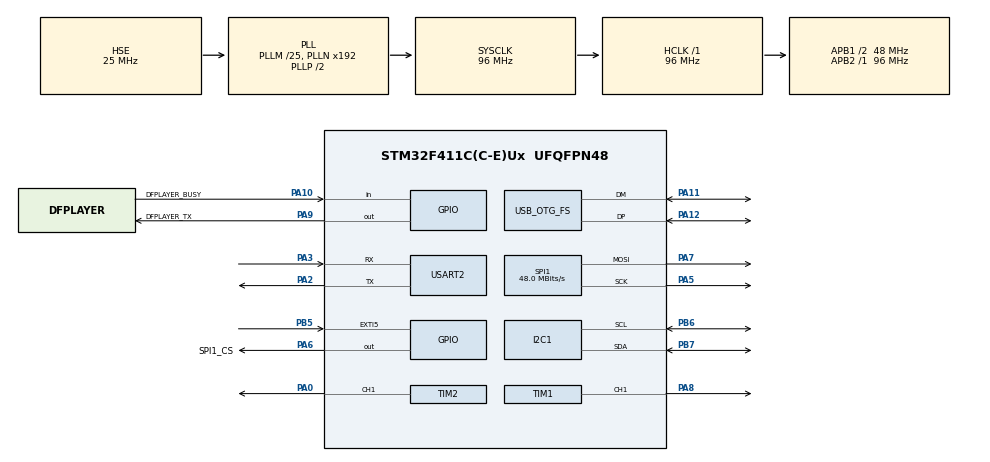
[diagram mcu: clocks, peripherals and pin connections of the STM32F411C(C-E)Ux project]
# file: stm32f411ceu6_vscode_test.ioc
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Dma.Request0=USART2_RX
Dma.Request1=USART2_TX
Dma.Request2=TIM2_CH1
Dma.TIM2_CH1.2.Direction=DMA_MEMORY_TO_PERIPH
Dma.TIM2_CH1.2.FIFOMode=DMA_FIFOMODE_DISABLE
Dma.TIM2_CH1.2.Instance=DMA1_Stream5
Dma.TIM2_CH1.2.MemDataAlignment=DMA_MDATAALIGN_WORD
Dma.TIM2_CH1.2.MemInc=DMA_MINC_ENABLE
Dma.TIM2_CH1.2.Mode=DMA_NORMAL
Dma.TIM2_CH1.2.PeriphDataAlignment=DMA_PDATAALIGN_WORD
Dma.TIM2_CH1.2.PeriphInc=DMA_PINC_DISABLE
Dma.TIM2_CH1.2.Priority=DMA_PRIORITY_HIGH
Dma.USART2_RX.0.Direction=DMA_PERIPH_TO_MEMORY
Dma.USART2_RX.0.FIFOMode=DMA_FIFOMODE_DISABLE
Dma.USART2_RX.0.Instance=DMA1_Stream7
Dma.USART2_RX.0.MemDataAlignment=DMA_MDATAALIGN_BYTE
Dma.USART2_RX.0.MemInc=DMA_MINC_ENABLE
Dma.USART2_RX.0.Mode=DMA_CIRCULAR
Dma.USART2_RX.0.PeriphDataAlignment=DMA_PDATAALIGN_BYTE
Dma.USART2_RX.0.PeriphInc=DMA_PINC_DISABLE
Dma.USART2_RX.0.Priority=DMA_PRIORITY_MEDIUM
Dma.USART2_TX.1.Direction=DMA_MEMORY_TO_PERIPH
Dma.USART2_TX.1.FIFOMode=DMA_FIFOMODE_DISABLE
Dma.USART2_TX.1.Instance=DMA1_Stream6
Dma.USART2_TX.1.MemDataAlignment=DMA_MDATAALIGN_BYTE
Dma.USART2_TX.1.MemInc=DMA_MINC_ENABLE
Dma.USART2_TX.1.Mode=DMA_NORMAL
Dma.USART2_TX.1.PeriphDataAlignment=DMA_PDATAALIGN_BYTE
Dma.USART2_TX.1.PeriphInc=DMA_PINC_DISABLE
Dma.USART2_TX.1.Priority=DMA_PRIORITY_MEDIUM
Mcu.Family=STM32F4
Mcu.Name=STM32F411C(C-E)Ux
Mcu.Package=UFQFPN48
NVIC.DMA1_Stream5_IRQn=true\:0\:0\:true\:false\:true\:false\:true\:true
NVIC.DMA1_Stream6_IRQn=true\:5\:0\:true\:false\:true\:false\:true\:true
NVIC.DMA1_Stream7_IRQn=true\:5\:0\:false\:false\:true\:false\:true\:true
NVIC.EXTI9_5_IRQn=true\:0\:0\:false\:false\:true\:true\:true\:true
NVIC.OTG_FS_IRQn=true\:0\:0\:false\:false\:true\:false\:true\:true
NVIC.PriorityGroup=NVIC_PRIORITYGROUP_4
NVIC.TIM2_IRQn=true\:0\:0\:false\:false\:true\:true\:true\:true
NVIC.TIM3_IRQn=true\:0\:0\:false\:false\:true\:true\:true\:true
NVIC.USART2_IRQn=true\:5\:0\:true\:false\:true\:true\:true\:true
PA0-WKUP.GPIO_Speed=GPIO_SPEED_FREQ_VERY_HIGH
PA0-WKUP.Signal=S_TIM2_CH1_ETR
PA10.GPIO_Label=DFPLAYER_BUSY
PA10.GPIO_PuPd=GPIO_PULLUP
PA10.Signal=GPIO_Input
PA11.Mode=Device_Only
PA11.Signal=USB_OTG_FS_DM
PA12.Mode=Device_Only
PA12.Signal=USB_OTG_FS_DP
PA13.Mode=JTAG_4_pins
PA13.Signal=SYS_JTMS-SWDIO
PA14.Mode=JTAG_4_pins
PA14.Signal=SYS_JTCK-SWCLK
PA15.Mode=JTAG_4_pins
PA15.Signal=SYS_JTDI
PA2.Mode=Asynchronous
PA2.Signal=USART2_TX
PA3.Mode=Asynchronous
PA3.Signal=USART2_RX
PA5.Mode=TX_Only_Simplex_Unidirect_Master
PA5.Signal=SPI1_SCK
PA6.GPIO_Label=SPI1_CS
PA6.Signal=GPIO_Output
PA7.Mode=TX_Only_Simplex_Unidirect_Master
PA7.Signal=SPI1_MOSI
PA8.Signal=S_TIM1_CH1
PA9.GPIO_Label=DFPLAYER_TX
PA9.GPIO_Speed=GPIO_SPEED_FREQ_HIGH
PA9.PinState=GPIO_PIN_SET
PA9.Signal=GPIO_Output
PB3.Mode=JTAG_4_pins
PB3.Signal=SYS_JTDO-SWO
PB5.Signal=GPXTI5
PB6.Mode=I2C
PB6.Signal=I2C1_SCL
PB7.Mode=I2C
PB7.Signal=I2C1_SDA
PC14-OSC32_IN.Mode=LSE-External-Oscillator
PC14-OSC32_IN.Signal=RCC_OSC32_IN
PC15-OSC32_OUT.Mode=LSE-External-Oscillator
PC15-OSC32_OUT.Signal=RCC_OSC32_OUT
PH0\ -\ OSC_IN.Mode=HSE-External-Oscillator
PH0\ -\ OSC_IN.Signal=RCC_OSC_IN
PH1\ -\ OSC_OUT.Mode=HSE-External-Oscillator
PH1\ -\ OSC_OUT.Signal=RCC_OSC_OUT
ProjectManager.HeapSize=0x200
ProjectManager.StackSize=0x400
ProjectManager.TargetToolchain=CMake
RCC.48MHZClocksFreq_Value=48000000
RCC.AHBFreq_Value=96000000
RCC.APB1CLKDivider=RCC_HCLK_DIV2
RCC.APB1Freq_Value=48000000
RCC.APB1TimFreq_Value=96000000
RCC.APB2Freq_Value=96000000
RCC.APB2TimFreq_Value=96000000
RCC.CortexFreq_Value=96000000
RCC.HCLKFreq_Value=96000000
RCC.HSE_VALUE=25000000
RCC.HSI_VALUE=16000000
RCC.PLLM=25
RCC.SYSCLKFreq_VALUE=96000000
RCC.SYSCLKSource=RCC_SYSCLKSOURCE_PLLCLK
RCC.VCOOutputFreq_Value=192000000
RTC.HourFormat=RTC_HOURFORMAT_12
RTC.Hours=10
RTC.Minutes=23
RTC.Seconds=45
SH.S_TIM1_CH1.0=TIM1_CH1,PWM Generation1 CH1
SH.S_TIM2_CH1_ETR.0=TIM2_CH1,PWM Generation1 CH1
SPI1.BaudRatePrescaler=SPI_BAUDRATEPRESCALER_2
SPI1.CalculateBaudRate=48.0 MBits/s
SPI1.Direction=SPI_DIRECTION_2LINES
SPI1.Mode=SPI_MODE_MASTER
SPI1.VirtualType=VM_MASTER
TIM1.Channel-PWM\ Generation1\ CH1=TIM_CHANNEL_1
TIM1.Period=49999
TIM1.Pulse-PWM\ Generation1\ CH1=35639
TIM2.AutoReloadPreload=TIM_AUTORELOAD_PRELOAD_ENABLE
TIM2.Channel-PWM\ Generation1\ CH1=TIM_CHANNEL_1
TIM2.Period=119
TIM3.Period=999
TIM3.Prescaler=95
USART2.VirtualMode=VM_ASYNC
USB_DEVICE.CLASS_NAME_FS=MSC
USB_DEVICE.VirtualMode=Msc
USB_DEVICE.VirtualModeFS=Msc_FS
USB_OTG_FS.VirtualMode=Device_Only
VP_RTC_VS_RTC_Activate.Mode=RTC_Enabled
VP_RTC_VS_RTC_Calendar.Mode=RTC_Calendar
VP_TIM2_VS_ClockSourceINT.Mode=Internal
VP_TIM3_VS_ClockSourceINT.Mode=Internal
VP_USB_DEVICE_VS_USB_DEVICE_MSC_FS.Mode=MSC_FS
board=custom

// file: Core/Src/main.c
/* USER CODE BEGIN Header */
/**
 ******************************************************************************
 * @file           : main.c
 * @brief          : Main program body
 ******************************************************************************
 * @attention
 *
 * Copyright (c) 2026 STMicroelectronics.
 * All rights reserved.
 *
 * This software is licensed under terms that can be found in the LICENSE file
 * in the root directory of this software component.
 * If no LICENSE file comes with this software, it is provided AS-IS.
 *
 ******************************************************************************
 */
/* USER CODE END Header */
#include "main.h"
#include "usb_device.h"

/* USER CODE BEGIN Includes */
#include "application.h"
/* USER CODE END Includes */

I2C_HandleTypeDef hi2c1;

RTC_HandleTypeDef hrtc;

SPI_HandleTypeDef hspi1;

TIM_HandleTypeDef htim1;
TIM_HandleTypeDef htim2;
TIM_HandleTypeDef htim3;
DMA_HandleTypeDef hdma_tim2_ch1;

UART_HandleTypeDef huart2;
DMA_HandleTypeDef hdma_usart2_rx;
DMA_HandleTypeDef hdma_usart2_tx;

void SystemClock_Config(void);
static void MX_GPIO_Init(void);
static void MX_DMA_Init(void);
static void MX_SPI1_Init(void);
static void MX_TIM1_Init(void);
static void MX_RTC_Init(void);
static void MX_USART2_UART_Init(void);
static void MX_TIM3_Init(void);
static void MX_I2C1_Init(void);
static void MX_TIM2_Init(void);

int main(void)
{

  /* MCU Configuration--------------------------------------------------------*/

  /* Reset of all peripherals, Initializes the Flash interface and the Systick. */
  HAL_Init();

  /* Configure the system clock */
  SystemClock_Config();

  /* USER CODE BEGIN SysInit */
  Application.config();
  /* USER CODE END SysInit */

  /* Initialize all configured peripherals */
  MX_GPIO_Init();
  MX_DMA_Init();
  MX_SPI1_Init();
  MX_TIM1_Init();
  MX_RTC_Init();
  MX_USART2_UART_Init();
  MX_USB_DEVICE_Init();
  MX_TIM3_Init();
  MX_I2C1_Init();
  MX_TIM2_Init();
  /* USER CODE BEGIN 2 */
  Application.init();
  /* USER CODE END 2 */

  /* Infinite loop */
  /* USER CODE BEGIN WHILE */
  while (1) {
    Application.run();
    /* USER CODE END WHILE */

  }
}

void SystemClock_Config(void)
{
  RCC_OscInitTypeDef RCC_OscInitStruct = {0};
  RCC_ClkInitTypeDef RCC_ClkInitStruct = {0};

  /** Configure the main internal regulator output voltage
  */
  __HAL_RCC_PWR_CLK_ENABLE();
  __HAL_PWR_VOLTAGESCALING_CONFIG(PWR_REGULATOR_VOLTAGE_SCALE1);

  /** Initializes the RCC Oscillators according to the specified parameters
  * in the RCC_OscInitTypeDef structure.
  */
  RCC_OscInitStruct.OscillatorType = RCC_OSCILLATORTYPE_LSI|RCC_OSCILLATORTYPE_HSE;
  RCC_OscInitStruct.HSEState = RCC_HSE_ON;
  RCC_OscInitStruct.LSIState = RCC_LSI_ON;
  RCC_OscInitStruct.PLL.PLLState = RCC_PLL_ON;
  RCC_OscInitStruct.PLL.PLLSource = RCC_PLLSOURCE_HSE;
  RCC_OscInitStruct.PLL.PLLM = 25;
  RCC_OscInitStruct.PLL.PLLN = 192;
  RCC_OscInitStruct.PLL.PLLP = RCC_PLLP_DIV2;
  RCC_OscInitStruct.PLL.PLLQ = 4;
  if (HAL_RCC_OscConfig(&RCC_OscInitStruct) != HAL_OK)
  {
    Error_Handler();
  }

  /** Initializes the CPU, AHB and APB buses clocks
  */
  RCC_ClkInitStruct.ClockType = RCC_CLOCKTYPE_HCLK|RCC_CLOCKTYPE_SYSCLK
                              |RCC_CLOCKTYPE_PCLK1|RCC_CLOCKTYPE_PCLK2;
  RCC_ClkInitStruct.SYSCLKSource = RCC_SYSCLKSOURCE_PLLCLK;
  RCC_ClkInitStruct.AHBCLKDivider = RCC_SYSCLK_DIV1;
  RCC_ClkInitStruct.APB1CLKDivider = RCC_HCLK_DIV2;
  RCC_ClkInitStruct.APB2CLKDivider = RCC_HCLK_DIV1;

  if (HAL_RCC_ClockConfig(&RCC_ClkInitStruct, FLASH_LATENCY_3) != HAL_OK)
  {
    Error_Handler();
  }
}

static void MX_I2C1_Init(void)
{

  hi2c1.Instance = I2C1;
  hi2c1.Init.ClockSpeed = 100000;
  hi2c1.Init.DutyCycle = I2C_DUTYCYCLE_2;
  hi2c1.Init.OwnAddress1 = 0;
  hi2c1.Init.AddressingMode = I2C_ADDRESSINGMODE_7BIT;
  hi2c1.Init.DualAddressMode = I2C_DUALADDRESS_DISABLE;
  hi2c1.Init.OwnAddress2 = 0;
  hi2c1.Init.GeneralCallMode = I2C_GENERALCALL_DISABLE;
  hi2c1.Init.NoStretchMode = I2C_NOSTRETCH_DISABLE;
  if (HAL_I2C_Init(&hi2c1) != HAL_OK)
  {
    Error_Handler();
  }

}

static void MX_RTC_Init(void)
{

  RTC_TimeTypeDef sTime = {0};
  RTC_DateTypeDef sDate = {0};

  /** Initialize RTC Only
  */
  hrtc.Instance = RTC;
  hrtc.Init.HourFormat = RTC_HOURFORMAT_12;
  hrtc.Init.AsynchPrediv = 127;
  hrtc.Init.SynchPrediv = 255;
  hrtc.Init.OutPut = RTC_OUTPUT_DISABLE;
  hrtc.Init.OutPutPolarity = RTC_OUTPUT_POLARITY_HIGH;
  hrtc.Init.OutPutType = RTC_OUTPUT_TYPE_OPENDRAIN;
  if (HAL_RTC_Init(&hrtc) != HAL_OK)
  {
    Error_Handler();
  }

  /** Initialize RTC and set the Time and Date
  */
  sTime.Hours = 0x10;
  sTime.Minutes = 0x23;
  sTime.Seconds = 0x45;
  sTime.TimeFormat = RTC_HOURFORMAT12_AM;
  sTime.DayLightSaving = RTC_DAYLIGHTSAVING_NONE;
  sTime.StoreOperation = RTC_STOREOPERATION_RESET;
  if (HAL_RTC_SetTime(&hrtc, &sTime, RTC_FORMAT_BCD) != HAL_OK)
  {
    Error_Handler();
  }
  sDate.WeekDay = RTC_WEEKDAY_MONDAY;
  sDate.Month = RTC_MONTH_JANUARY;
  sDate.Date = 0x1;
  sDate.Year = 0x0;

  if (HAL_RTC_SetDate(&hrtc, &sDate, RTC_FORMAT_BCD) != HAL_OK)
  {
    Error_Handler();
  }

}

static void MX_SPI1_Init(void)
{

  /* SPI1 parameter configuration*/
  hspi1.Instance = SPI1;
  hspi1.Init.Mode = SPI_MODE_MASTER;
  hspi1.Init.Direction = SPI_DIRECTION_2LINES;
  hspi1.Init.DataSize = SPI_DATASIZE_8BIT;
  hspi1.Init.CLKPolarity = SPI_POLARITY_LOW;
  hspi1.Init.CLKPhase = SPI_PHASE_1EDGE;
  hspi1.Init.NSS = SPI_NSS_SOFT;
  hspi1.Init.BaudRatePrescaler = SPI_BAUDRATEPRESCALER_2;
  hspi1.Init.FirstBit = SPI_FIRSTBIT_MSB;
  hspi1.Init.TIMode = SPI_TIMODE_DISABLE;
  hspi1.Init.CRCCalculation = SPI_CRCCALCULATION_DISABLE;
  hspi1.Init.CRCPolynomial = 10;
  if (HAL_SPI_Init(&hspi1) != HAL_OK)
  {
    Error_Handler();
  }

}

static void MX_TIM1_Init(void)
{

  TIM_MasterConfigTypeDef sMasterConfig = {0};
  TIM_OC_InitTypeDef sConfigOC = {0};
  TIM_BreakDeadTimeConfigTypeDef sBreakDeadTimeConfig = {0};

  htim1.Instance = TIM1;
  htim1.Init.Prescaler = 0;
  htim1.Init.CounterMode = TIM_COUNTERMODE_UP;
  htim1.Init.Period = 49999;
  htim1.Init.ClockDivision = TIM_CLOCKDIVISION_DIV1;
  htim1.Init.RepetitionCounter = 0;
  htim1.Init.AutoReloadPreload = TIM_AUTORELOAD_PRELOAD_DISABLE;
  if (HAL_TIM_PWM_Init(&htim1) != HAL_OK)
  {
    Error_Handler();
  }
  sMasterConfig.MasterOutputTrigger = TIM_TRGO_RESET;
  sMasterConfig.MasterSlaveMode = TIM_MASTERSLAVEMODE_DISABLE;
  if (HAL_TIMEx_MasterConfigSynchronization(&htim1, &sMasterConfig) != HAL_OK)
  {
    Error_Handler();
  }
  sConfigOC.OCMode = TIM_OCMODE_PWM1;
  sConfigOC.Pulse = 35639;
  sConfigOC.OCPolarity = TIM_OCPOLARITY_HIGH;
  sConfigOC.OCNPolarity = TIM_OCNPOLARITY_HIGH;
  sConfigOC.OCFastMode = TIM_OCFAST_DISABLE;
  sConfigOC.OCIdleState = TIM_OCIDLESTATE_RESET;
  sConfigOC.OCNIdleState = TIM_OCNIDLESTATE_RESET;
  if (HAL_TIM_PWM_ConfigChannel(&htim1, &sConfigOC, TIM_CHANNEL_1) != HAL_OK)
  {
    Error_Handler();
  }
  sBreakDeadTimeConfig.OffStateRunMode = TIM_OSSR_DISABLE;
  sBreakDeadTimeConfig.OffStateIDLEMode = TIM_OSSI_DISABLE;
  sBreakDeadTimeConfig.LockLevel = TIM_LOCKLEVEL_OFF;
  sBreakDeadTimeConfig.DeadTime = 0;
  sBreakDeadTimeConfig.BreakState = TIM_BREAK_DISABLE;
  sBreakDeadTimeConfig.BreakPolarity = TIM_BREAKPOLARITY_HIGH;
  sBreakDeadTimeConfig.AutomaticOutput = TIM_AUTOMATICOUTPUT_DISABLE;
  if (HAL_TIMEx_ConfigBreakDeadTime(&htim1, &sBreakDeadTimeConfig) != HAL_OK)
  {
    Error_Handler();
  }
  HAL_TIM_MspPostInit(&htim1);

}

static void MX_TIM2_Init(void)
{

  TIM_ClockConfigTypeDef sClockSourceConfig = {0};
  TIM_MasterConfigTypeDef sMasterConfig = {0};
  TIM_OC_InitTypeDef sConfigOC = {0};

  htim2.Instance = TIM2;
  htim2.Init.Prescaler = 0;
  htim2.Init.CounterMode = TIM_COUNTERMODE_UP;
  htim2.Init.Period = 119;
  htim2.Init.ClockDivision = TIM_CLOCKDIVISION_DIV1;
  htim2.Init.AutoReloadPreload = TIM_AUTORELOAD_PRELOAD_ENABLE;
  if (HAL_TIM_Base_Init(&htim2) != HAL_OK)
  {
    Error_Handler();
  }
  sClockSourceConfig.ClockSource = TIM_CLOCKSOURCE_INTERNAL;
  if (HAL_TIM_ConfigClockSource(&htim2, &sClockSourceConfig) != HAL_OK)
  {
    Error_Handler();
  }
  if (HAL_TIM_PWM_Init(&htim2) != HAL_OK)
  {
    Error_Handler();
  }
  sMasterConfig.MasterOutputTrigger = TIM_TRGO_RESET;
  sMasterConfig.MasterSlaveMode = TIM_MASTERSLAVEMODE_DISABLE;
  if (HAL_TIMEx_MasterConfigSynchronization(&htim2, &sMasterConfig) != HAL_OK)
  {
    Error_Handler();
  }
  sConfigOC.OCMode = TIM_OCMODE_PWM1;
  sConfigOC.Pulse = 0;
  sConfigOC.OCPolarity = TIM_OCPOLARITY_HIGH;
  sConfigOC.OCFastMode = TIM_OCFAST_DISABLE;
  if (HAL_TIM_PWM_ConfigChannel(&htim2, &sConfigOC, TIM_CHANNEL_1) != HAL_OK)
  {
    Error_Handler();
  }
  HAL_TIM_MspPostInit(&htim2);

}

static void MX_TIM3_Init(void)
{

  TIM_ClockConfigTypeDef sClockSourceConfig = {0};
  TIM_MasterConfigTypeDef sMasterConfig = {0};

  htim3.Instance = TIM3;
  htim3.Init.Prescaler = 95;
  htim3.Init.CounterMode = TIM_COUNTERMODE_UP;
  htim3.Init.Period = 999;
  htim3.Init.ClockDivision = TIM_CLOCKDIVISION_DIV1;
  htim3.Init.AutoReloadPreload = TIM_AUTORELOAD_PRELOAD_DISABLE;
  if (HAL_TIM_Base_Init(&htim3) != HAL_OK)
  {
    Error_Handler();
  }
  sClockSourceConfig.ClockSource = TIM_CLOCKSOURCE_INTERNAL;
  if (HAL_TIM_ConfigClockSource(&htim3, &sClockSourceConfig) != HAL_OK)
  {
    Error_Handler();
  }
  sMasterConfig.MasterOutputTrigger = TIM_TRGO_RESET;
  sMasterConfig.MasterSlaveMode = TIM_MASTERSLAVEMODE_DISABLE;
  if (HAL_TIMEx_MasterConfigSynchronization(&htim3, &sMasterConfig) != HAL_OK)
  {
    Error_Handler();
  }

}

static void MX_USART2_UART_Init(void)
{

  huart2.Instance = USART2;
  huart2.Init.BaudRate = 115200;
  huart2.Init.WordLength = UART_WORDLENGTH_8B;
  huart2.Init.StopBits = UART_STOPBITS_1;
  huart2.Init.Parity = UART_PARITY_NONE;
  huart2.Init.Mode = UART_MODE_TX_RX;
  huart2.Init.HwFlowCtl = UART_HWCONTROL_NONE;
  huart2.Init.OverSampling = UART_OVERSAMPLING_16;
  if (HAL_UART_Init(&huart2) != HAL_OK)
  {
    Error_Handler();
  }

}

static void MX_DMA_Init(void)
{

  /* DMA controller clock enable */
  __HAL_RCC_DMA1_CLK_ENABLE();

  /* DMA interrupt init */
  /* DMA1_Stream5_IRQn interrupt configuration */
  HAL_NVIC_SetPriority(DMA1_Stream5_IRQn, 0, 0);
  HAL_NVIC_EnableIRQ(DMA1_Stream5_IRQn);
  /* DMA1_Stream6_IRQn interrupt configuration */
  HAL_NVIC_SetPriority(DMA1_Stream6_IRQn, 5, 0);
  HAL_NVIC_EnableIRQ(DMA1_Stream6_IRQn);
  /* DMA1_Stream7_IRQn interrupt configuration */
  HAL_NVIC_SetPriority(DMA1_Stream7_IRQn, 5, 0);
  HAL_NVIC_EnableIRQ(DMA1_Stream7_IRQn);

}

static void MX_GPIO_Init(void)
{
  GPIO_InitTypeDef GPIO_InitStruct = {0};

  /* GPIO Ports Clock Enable */
  __HAL_RCC_GPIOC_CLK_ENABLE();
  __HAL_RCC_GPIOH_CLK_ENABLE();
  __HAL_RCC_GPIOA_CLK_ENABLE();
  __HAL_RCC_GPIOB_CLK_ENABLE();

  /*Configure GPIO pin Output Level */
  HAL_GPIO_WritePin(SPI1_CS_GPIO_Port, SPI1_CS_Pin, GPIO_PIN_RESET);

  /*Configure GPIO pin Output Level */
  HAL_GPIO_WritePin(DFPLAYER_TX_GPIO_Port, DFPLAYER_TX_Pin, GPIO_PIN_SET);

  /*Configure GPIO pin : SPI1_CS_Pin */
  GPIO_InitStruct.Pin = SPI1_CS_Pin;
  GPIO_InitStruct.Mode = GPIO_MODE_OUTPUT_PP;
  GPIO_InitStruct.Pull = GPIO_NOPULL;
  GPIO_InitStruct.Speed = GPIO_SPEED_FREQ_LOW;
  HAL_GPIO_Init(SPI1_CS_GPIO_Port, &GPIO_InitStruct);

  /*Configure GPIO pin : DFPLAYER_TX_Pin */
  GPIO_InitStruct.Pin = DFPLAYER_TX_Pin;
  GPIO_InitStruct.Mode = GPIO_MODE_OUTPUT_PP;
  GPIO_InitStruct.Pull = GPIO_NOPULL;
  GPIO_InitStruct.Speed = GPIO_SPEED_FREQ_HIGH;
  HAL_GPIO_Init(DFPLAYER_TX_GPIO_Port, &GPIO_InitStruct);

  /*Configure GPIO pin : DFPLAYER_BUSY_Pin */
  GPIO_InitStruct.Pin = DFPLAYER_BUSY_Pin;
  GPIO_InitStruct.Mode = GPIO_MODE_INPUT;
  GPIO_InitStruct.Pull = GPIO_PULLUP;
  HAL_GPIO_Init(DFPLAYER_BUSY_GPIO_Port, &GPIO_InitStruct);

  /*Configure GPIO pin : PB5 */
  GPIO_InitStruct.Pin = GPIO_PIN_5;
  GPIO_InitStruct.Mode = GPIO_MODE_IT_RISING;
  GPIO_InitStruct.Pull = GPIO_NOPULL;
  HAL_GPIO_Init(GPIOB, &GPIO_InitStruct);

  /* EXTI interrupt init*/
  HAL_NVIC_SetPriority(EXTI9_5_IRQn, 0, 0);
  HAL_NVIC_EnableIRQ(EXTI9_5_IRQn);

}

void Error_Handler(void)
{
  __disable_irq();
  while (1) {
  }
}
